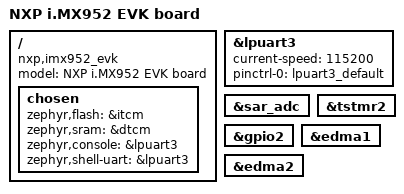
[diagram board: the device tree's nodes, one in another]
/*
 * SPDX-FileCopyrightText: Copyright 2026 NXP
 *
 * SPDX-License-Identifier: Apache-2.0
 */

/dts-v1/;

#include <nxp/imx/nxp_imx952_m7.dtsi>
#include "imx952_evk-pinctrl.dtsi"
#include <dt-bindings/mipi_dsi/mipi_dsi.h>

/ {
	compatible = "nxp,imx952_evk";
	model = "NXP i.MX952 EVK board";

	chosen {
		/* TCM */
		zephyr,flash = &itcm;
		zephyr,sram = &dtcm;

		zephyr,console = &lpuart3;
		zephyr,shell-uart = &lpuart3;
	};
};

&lpuart3 {
	current-speed = <115200>;
	pinctrl-0 = <&lpuart3_default>;
	pinctrl-names = "default";
	status = "okay";
};

&sar_adc {
	status = "okay";
};

&tstmr2 {
	status = "okay";
};

&gpio2 {
	status = "okay";
};

&edma1 {
	status = "okay";
};

&edma2 {
	status = "okay";
};
